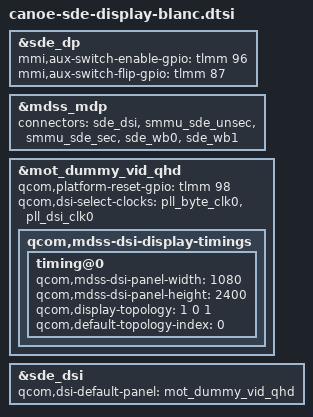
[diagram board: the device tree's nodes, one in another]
// SPDX-License-Identifier: BSD-3-Clause
/*
 * Copyright (c) 2024-2025, Qualcomm Innovation Center, Inc. All rights reserved.
 */

#include "canoe-sde-display.dtsi"
#include "dsi-panel-mot-dummy-qhd-video.dtsi"

&sde_dp {
	mmi,aux-switch-enable-gpio = <&tlmm 96 0>;
	mmi,aux-switch-flip-gpio = <&tlmm 87 0>;
    /delete-property/ qcom,dp-aux-switch;
};


&mdss_mdp {
	connectors = <&sde_dsi &smmu_sde_unsec &smmu_sde_sec &sde_wb0 &sde_wb1>;
};


&mot_dummy_vid_qhd {
       qcom,mdss-dsi-display-timings {
                timing@0{
                       qcom,mdss-dsi-panel-width = <1080>;
                       qcom,mdss-dsi-panel-height = <2400>;
               };
       };
};

&mot_dummy_vid_qhd {
	qcom,platform-reset-gpio = <&tlmm 98 0>;

	qcom,dsi-select-clocks = "pll_byte_clk0", "pll_dsi_clk0";
	qcom,mdss-dsi-display-timings {
		timing@0 {
			qcom,display-topology = <1 0 1>;
			qcom,default-topology-index = <0>;
		};
	};
};

&sde_dsi {
	qcom,dsi-default-panel = <&mot_dummy_vid_qhd>;
};

